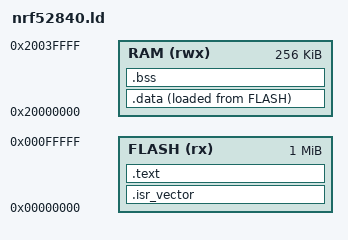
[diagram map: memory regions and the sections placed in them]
MEMORY
{
    FLASH (rx)  : ORIGIN = 0x00000000, LENGTH = 1M
    RAM   (rwx) : ORIGIN = 0x20000000, LENGTH = 256K
}

_estack = ORIGIN(RAM) + LENGTH(RAM);

SECTIONS
{
    .isr_vector ORIGIN(FLASH):
    {
        KEEP(*(.isr_vector))
    } > FLASH

    .text :
    {
        *(.text*)
        *(.rodata*)
    } > FLASH

    .data :
    {
        . = ALIGN(4);
        _sdata = .;

        *(.data*)

        . = ALIGN(4);
        _edata = .;
    } > RAM AT > FLASH

    _sidata = LOADADDR(.data);

    .bss :
    {
        . = ALIGN(4);
        _sbss = .;

        *(.bss*)
        *(COMMON)

        . = ALIGN(4);
        _ebss = .;
    } > RAM
}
